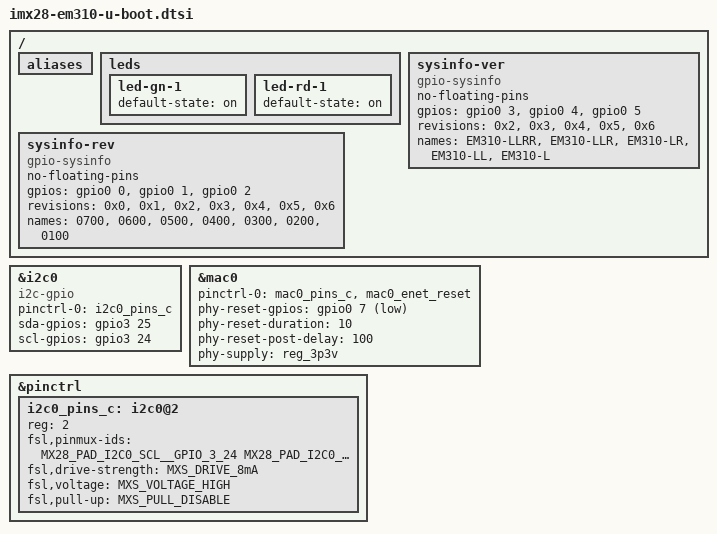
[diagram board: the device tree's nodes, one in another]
// SPDX-License-Identifier: GPL-2.0-or-later
/*
 * Copyright (c) 2023-2026 TQ-Systems GmbH <u-boot@ew.tq-group.com>,
 * D-82229 Seefeld, Germany.
 * Author: Michael Krummsdorf
 */

#include "imx28-u-boot.dtsi"

/ {
	aliases {
		/delete-property/ ethernet1;
	};

	leds {
		led-gn-1 {
			default-state = "on";
		};

		led-rd-1 {
			default-state = "on";
		};
	};
	sysinfo-ver {
		compatible = "gpio-sysinfo";
		no-floating-pins;
		gpios =
			<&gpio0 3 GPIO_ACTIVE_HIGH>, /* HW.VER0 */
			<&gpio0 4 GPIO_ACTIVE_HIGH>, /* HW.VER1 */
			<&gpio0 5 GPIO_ACTIVE_HIGH>; /* HW.VER2 */

		revisions = <0x2>, <0x3>, <0x4>, <0x5>, <0x6>;
		names =	"EM310-LLRR",	/* 010   PD PU PD */
			"EM310-LLR",	/* 011   PD PU PU */
			"EM310-LR",	/* 100   PU PD PD */
			"EM310-LL",	/* 101   PU PD PU */
			"EM310-L";	/* 110   PU PU PD */
	};

	sysinfo-rev {
		compatible = "gpio-sysinfo";
		no-floating-pins;
		gpios =
			<&gpio0 0 GPIO_ACTIVE_HIGH>, /* HW.REV0 */
			<&gpio0 1 GPIO_ACTIVE_HIGH>, /* HW.REV1 */
			<&gpio0 2 GPIO_ACTIVE_HIGH>; /* HW.REV2 */

		revisions = <0x0>, <0x1>, <0x2>, <0x3>, <0x4>, <0x5>, <0x6>;
		names = "0700", "0600", "0500", "0400", "0300", "0200", "0100";
	};

};

&i2c0 {
	/* No i2c-mxs driver in U-Boot, use i2c-gpio */
	compatible = "i2c-gpio";
	pinctrl-0 = <&i2c0_pins_c>;
	sda-gpios = <&gpio3 25 GPIO_ACTIVE_HIGH>;
	scl-gpios = <&gpio3 24 GPIO_ACTIVE_HIGH>;
};

&mac0 {
	pinctrl-0 = <&mac0_pins_c>,
		    <&mac0_enet_reset>;
	/* U-Boot network as fixed-link, use generic reset */
	phy-reset-gpios = <&gpio0 7 GPIO_ACTIVE_LOW>;
	phy-reset-duration = <10>;
	phy-reset-post-delay = <100>;
	phy-supply = <&reg_3p3v>;
};

&pinctrl {
	i2c0_pins_c: i2c0@2 {
		reg = <2>;
		fsl,pinmux-ids = <
			MX28_PAD_I2C0_SCL__GPIO_3_24
			MX28_PAD_I2C0_SDA__GPIO_3_25
		>;
		fsl,drive-strength = <MXS_DRIVE_8mA>;
		fsl,voltage = <MXS_VOLTAGE_HIGH>;
		fsl,pull-up = <MXS_PULL_DISABLE>;
	};
};
